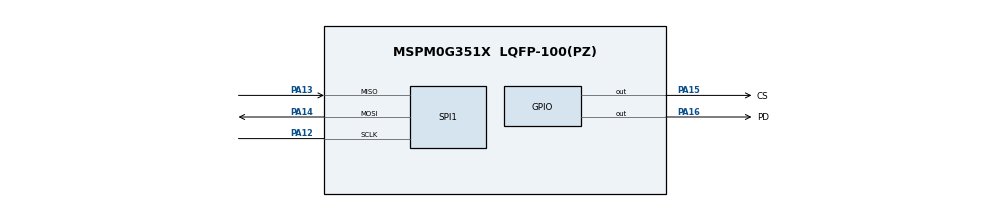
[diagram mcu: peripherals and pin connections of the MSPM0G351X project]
/**
 * @cliArgs --device "MSPM0G351X" --part "Default" --package "LQFP-100(PZ)" --product "mspm0_sdk@2.05.01.01"
 * @versions {"tool":"1.24.0+4110"}
 */

/**
 * Import the modules used in this configuration.
 */
const GPIO   = scripting.addModule("/ti/driverlib/GPIO", {}, false);
const GPIO1  = GPIO.addInstance();
const SPI    = scripting.addModule("/ti/driverlib/SPI", {}, false);
const SPI1   = SPI.addInstance();
const SYSCTL = scripting.addModule("/ti/driverlib/SYSCTL");

/**
 * Write custom configuration values to the imported modules.
 */
GPIO1.$name                         = "GPIO_GRP_0";
GPIO1.port                          = "PORTA";
GPIO1.associatedPins.create(2);
GPIO1.associatedPins[0].$name       = "CS";
GPIO1.associatedPins[0].pin.$assign = "PA15";
GPIO1.associatedPins[1].$name       = "PD";
GPIO1.associatedPins[1].pin.$assign = "PA16";

const Board = scripting.addModule("/ti/driverlib/Board", {}, false);

SPI1.$name                      = "SPI_0";
SPI1.peripheral.$assign         = "SPI0";
SPI1.peripheral.sclkPin.$assign = "PA12";
SPI1.peripheral.mosiPin.$assign = "PA14";
SPI1.peripheral.misoPin.$assign = "PA13";
SPI1.sclkPinConfig.$name        = "ti_driverlib_gpio_GPIOPinGeneric0";
SPI1.mosiPinConfig.$name        = "ti_driverlib_gpio_GPIOPinGeneric1";
SPI1.misoPinConfig.$name        = "ti_driverlib_gpio_GPIOPinGeneric2";
SPI1.cs0PinConfig.$name         = "ti_driverlib_gpio_GPIOPinGeneric3";

SYSCTL.forceDefaultClkConfig = true;
SYSCTL.clockTreeEn           = true;

/**
 * Pinmux solution for unlocked pins/peripherals. This ensures that minor changes to the automatic solver in a future
 * version of the tool will not impact the pinmux you originally saw.  These lines can be completely deleted in order to
 * re-solve from scratch.
 */
Board.peripheral.$suggestSolution          = "DEBUGSS";
Board.peripheral.swclkPin.$suggestSolution = "PA20";
Board.peripheral.swdioPin.$suggestSolution = "PA19";
SPI1.peripheral.cs0Pin.$suggestSolution    = "PA18";
